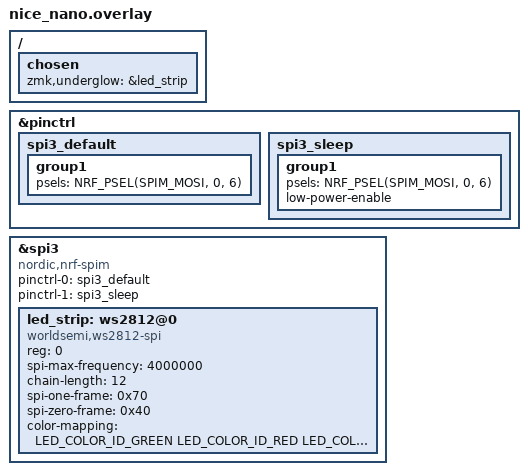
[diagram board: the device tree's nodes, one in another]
// RGB Underglow для nice!nano (nRF52840) на Lily58
#include <dt-bindings/led/led.h>
#include <dt-bindings/pinctrl/nrf-pinctrl.h>

/* Конфигурация пинов для SPI3 (WS2812) */
&pinctrl {
    spi3_default: spi3_default {
        group1 {
            psels = <NRF_PSEL(SPIM_MOSI, 0, 6)>;  /* P0.06 = Data In для светодиодов */
        };
    };

    spi3_sleep: spi3_sleep {
        group1 {
            psels = <NRF_PSEL(SPIM_MOSI, 0, 6)>;
            low-power-enable;
        };
    };
};

&spi3 {
    compatible = "nordic,nrf-spim";
    status = "okay";

    pinctrl-0 = <&spi3_default>;
    pinctrl-1 = <&spi3_sleep>;
    pinctrl-names = "default", "sleep";

    led_strip: ws2812@0 {
        compatible = "worldsemi,ws2812-spi";

        /* SPI параметры */
        reg = <0>;  /* Игнорируется, но обязателен для SPI bindings */
        spi-max-frequency = <4000000>;

        /* Параметры светодиодов */
        chain-length = <12>;  /* ⚠️ Количество LED на ОДНУ половину клавиатуры */
        spi-one-frame = <0x70>;
        spi-zero-frame = <0x40>;
        
        /* Порядок цветов: стандарт для WS2812 — GRB */
        color-mapping = <LED_COLOR_ID_GREEN
                         LED_COLOR_ID_RED
                         LED_COLOR_ID_BLUE>;
    };
};

/* Привязка к системе underglow ZMK */
/ {
    chosen {
        zmk,underglow = &led_strip;
    };
};
